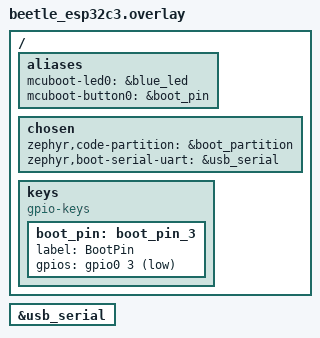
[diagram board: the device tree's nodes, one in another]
/*
 * Copyright (c) 2026 Dooleweerdt
 * SPDX-License-Identifier: Apache-2.0
 */

/ {
    aliases {
        mcuboot-led0 = &blue_led;
        mcuboot-button0 = &boot_pin;
    };

    chosen {
        zephyr,code-partition = &boot_partition;
        zephyr,boot-serial-uart = &usb_serial;
    };


	keys {
		compatible = "gpio-keys";

		boot_pin: boot_pin_3  {
			label = "BootPin";
			gpios = <&gpio0 3 (GPIO_PULL_UP | GPIO_ACTIVE_LOW)>;
		};
	};
};

&usb_serial {
	status = "okay";
};
